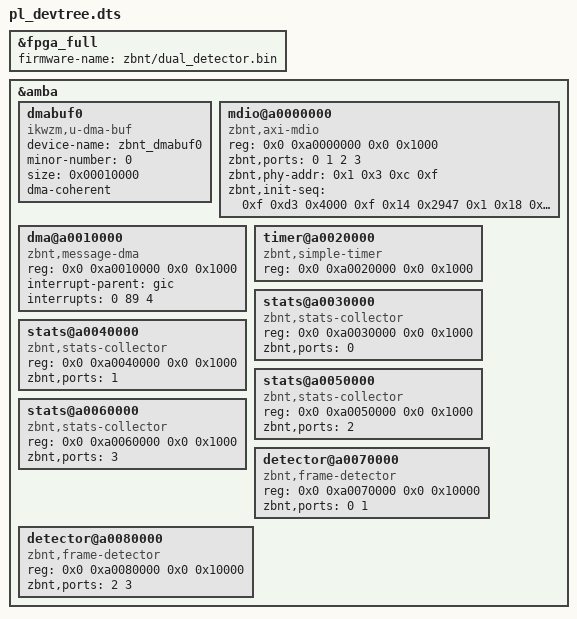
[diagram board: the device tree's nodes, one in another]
/*
	This Source Code Form is subject to the terms of the Mozilla Public
	License, v. 2.0. If a copy of the MPL was not distributed with this
	file, You can obtain one at https://mozilla.org/MPL/2.0/.
*/

/dts-v1/;
/plugin/;

/ {
	fragment@0 {
		target = <&fpga_full>;

		__overlay__ {
			firmware-name = "zbnt/dual_detector.bin";
		};
	};

	fragment@1 {
		target = <&amba>;

		__overlay__ {
			#address-cells = <2>;
			#size-cells = <2>;

			dmabuf0 {
				compatible = "ikwzm,u-dma-buf";
				device-name = "zbnt_dmabuf0";
				minor-number = <0>;
				size = <0x00010000>;
				dma-coherent;
			};

			mdio@a0000000 {
				compatible = "zbnt,axi-mdio", "generic-uio";
				reg = <0x0 0xa0000000 0x0 0x1000>;

				zbnt,ports = <0 1 2 3>;
				zbnt,phy-addr = <0x1 0x3 0xc 0xf>;

				zbnt,init-seq = <
					/* Enable 625MHz clock */
					0xf 0xd3 0x4000

					/* Disable SGMII auto-negotiation */
					0xf 0x14 0x2947

					/* Set LED modes */
					0x1 0x18 0x615b
					0x3 0x18 0x615b
					0xc 0x18 0x615b
					0xf 0x18 0x615b
				>;
			};

			dma@a0010000 {
				compatible = "zbnt,message-dma", "generic-uio";
				reg = <0x0 0xa0010000 0x0 0x1000>;

				interrupt-names = "irq0";
				interrupt-parent = <&gic>;
				interrupts = <0 89 4>;
			};

			timer@a0020000 {
				compatible = "zbnt,simple-timer", "generic-uio";
				reg = <0x0 0xa0020000 0x0 0x1000>;
			};

			stats@a0030000 {
				compatible = "zbnt,stats-collector", "generic-uio";
				reg = <0x0 0xa0030000 0x0 0x1000>;

				zbnt,ports = <0>;
			};

			stats@a0040000 {
				compatible = "zbnt,stats-collector", "generic-uio";
				reg = <0x0 0xa0040000 0x0 0x1000>;

				zbnt,ports = <1>;
			};

			stats@a0050000 {
				compatible = "zbnt,stats-collector", "generic-uio";
				reg = <0x0 0xa0050000 0x0 0x1000>;

				zbnt,ports = <2>;
			};

			stats@a0060000 {
				compatible = "zbnt,stats-collector", "generic-uio";
				reg = <0x0 0xa0060000 0x0 0x1000>;

				zbnt,ports = <3>;
			};

			detector@a0070000 {
				compatible = "zbnt,frame-detector", "generic-uio";
				reg = <0x0 0xa0070000 0x0 0x10000>;

				zbnt,ports = <0 1>;
			};

			detector@a0080000 {
				compatible = "zbnt,frame-detector", "generic-uio";
				reg = <0x0 0xa0080000 0x0 0x10000>;

				zbnt,ports = <2 3>;
			};
		};
	};
};
